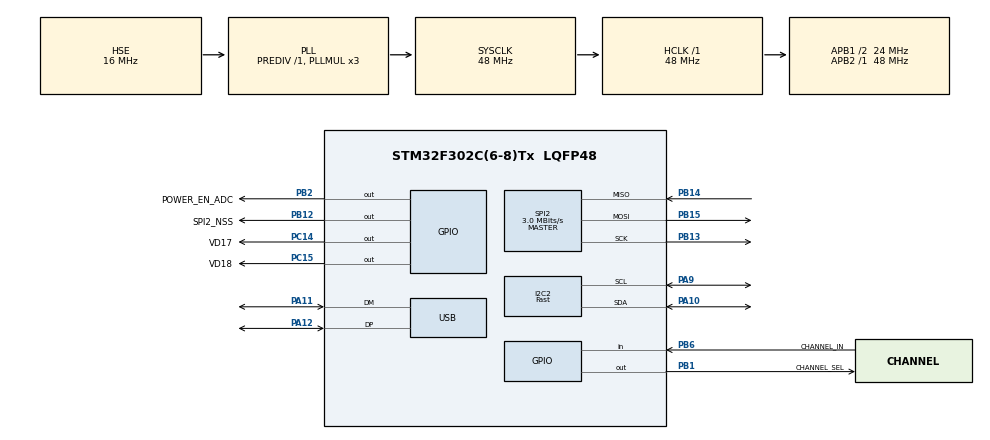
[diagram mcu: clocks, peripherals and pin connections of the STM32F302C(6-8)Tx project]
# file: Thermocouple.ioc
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I2C2.I2C_Speed_Mode=I2C_Fast
I2C2.Timing=0x0000020B
Mcu.Family=STM32F3
Mcu.Name=STM32F302C(6-8)Tx
Mcu.Package=LQFP48
NVIC.PriorityGroup=NVIC_PRIORITYGROUP_4
NVIC.USB_LP_CAN_RX0_IRQn=true\:0\:0\:false\:false\:true\:false\:true
PA10.Mode=I2C
PA10.Signal=I2C2_SDA
PA11.Mode=Device
PA11.Signal=USB_DM
PA12.Mode=Device
PA12.Signal=USB_DP
PA13.Mode=Serial_Wire
PA13.Signal=SYS_JTMS-SWDIO
PA14.Mode=Serial_Wire
PA14.Signal=SYS_JTCK-SWCLK
PA9.Mode=I2C
PA9.Signal=I2C2_SCL
PB1.GPIO_Label=CHANNEL_SEL
PB1.Signal=GPIO_Output
PB12.GPIO_Label=SPI2_NSS
PB12.GPIO_Speed=GPIO_SPEED_FREQ_HIGH
PB12.PinState=GPIO_PIN_SET
PB12.Signal=GPIO_Output
PB13.Mode=Full_Duplex_Master
PB13.Signal=SPI2_SCK
PB14.Mode=Full_Duplex_Master
PB14.Signal=SPI2_MISO
PB15.Mode=Full_Duplex_Master
PB15.Signal=SPI2_MOSI
PB2.GPIO_Label=POWER_EN_ADC
PB2.Signal=GPIO_Output
PB6.GPIO_Label=CHANNEL_IN
PB6.GPIO_PuPd=GPIO_PULLUP
PB6.Signal=GPIO_Input
PC14\ -\ OSC32_IN.GPIO_Label=VD17
PC14\ -\ OSC32_IN.Signal=GPIO_Output
PC15\ -\ OSC32_OUT.GPIO_Label=VD18
PC15\ -\ OSC32_OUT.Signal=GPIO_Output
PF0-OSC_IN.Mode=HSE-External-Oscillator
PF0-OSC_IN.Signal=RCC_OSC_IN
PF1-OSC_OUT.Mode=HSE-External-Oscillator
PF1-OSC_OUT.Signal=RCC_OSC_OUT
ProjectManager.HeapSize=0x200
ProjectManager.StackSize=0x400
ProjectManager.TargetToolchain=STM32CubeIDE
RCC.AHBFreq_Value=48000000
RCC.APB1CLKDivider=RCC_HCLK_DIV2
RCC.APB1Freq_Value=24000000
RCC.APB1TimFreq_Value=48000000
RCC.APB2Freq_Value=48000000
RCC.APB2TimFreq_Value=48000000
RCC.CortexFreq_Value=48000000
RCC.HCLKFreq_Value=48000000
RCC.HSE_VALUE=16000000
RCC.HSI_VALUE=8000000
RCC.LSE_VALUE=32768
RCC.PLLMUL=RCC_PLL_MUL3
RCC.SYSCLKFreq_VALUE=48000000
RCC.SYSCLKSourceVirtual=RCC_SYSCLKSOURCE_PLLCLK
RCC.USBFreq_Value=48000000
SPI2.BaudRatePrescaler=SPI_BAUDRATEPRESCALER_8
SPI2.CLKPhase=SPI_PHASE_2EDGE
SPI2.CalculateBaudRate=3.0 MBits/s
SPI2.DataSize=SPI_DATASIZE_8BIT
SPI2.Direction=SPI_DIRECTION_2LINES
SPI2.Mode=SPI_MODE_MASTER
SPI2.VirtualType=VM_MASTER
USB_DEVICE.CLASS_NAME_FS=CDC
USB_DEVICE.VirtualMode=Cdc
USB_DEVICE.VirtualModeFS=Cdc_FS
VP_USB_DEVICE_VS_USB_DEVICE_CDC_FS.Mode=CDC_FS
board=custom

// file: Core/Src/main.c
/* USER CODE BEGIN Header */
/**
  ******************************************************************************
  * @file           : main.c
  * @brief          : Main program body
  ******************************************************************************
  * @attention
  *
  * <h2><center>&copy; Copyright (c) 2021 STMicroelectronics.
  * All rights reserved.</center></h2>
  *
  * This software component is licensed by ST under BSD 3-Clause license,
  * the "License"; You may not use this file except in compliance with the
  * License. You may obtain a copy of the License at:
  *                        opensource.org/licenses/BSD-3-Clause
  *
  ******************************************************************************
  */
/* USER CODE END Header */
#include "main.h"
#include "usb_device.h"

/* USER CODE BEGIN Includes */
#include "thermocouple.h"
/* USER CODE END Includes */

I2C_HandleTypeDef hi2c2;

SPI_HandleTypeDef hspi2;

void SystemClock_Config(void);
static void MX_GPIO_Init(void);
static void MX_SPI2_Init(void);
static void MX_I2C2_Init(void);

int main(void)
{

  /* MCU Configuration--------------------------------------------------------*/

  /* Reset of all peripherals, Initializes the Flash interface and the Systick. */
  HAL_Init();

  /* Configure the system clock */
  SystemClock_Config();

  /* Initialize all configured peripherals */
  MX_GPIO_Init();
  MX_SPI2_Init();
  MX_USB_DEVICE_Init();
  MX_I2C2_Init();
  /* USER CODE BEGIN 2 */
  POWER_EN_ADC_GPIO_Port->BSRR = (uint32_t)POWER_EN_ADC_Pin;  //+3,3A_ISO1(DA3), +3,3V_ISO1(DA4) -- ON
  //CHANNEL_SEL_GPIO_Port->BSRR   = (uint32_t)CHANNEL_SEL_Pin;   //Analog Switches COM1 or COM2
  CHANNEL_SEL_GPIO_Port->BRR   = (uint32_t)CHANNEL_SEL_Pin;   //Analog Switches COM1 or COM2

  VD17_GPIO_Port->BSRR = (uint32_t)VD17_Pin;
  VD18_GPIO_Port->BSRR = (uint32_t)VD18_Pin;

  init_TMP112();
  MAX31856_config();
  /* USER CODE END 2 */

  /* Infinite loop */
  /* USER CODE BEGIN WHILE */
  while (1)
  {
    if(CHANNEL_IN_GPIO_Port->IDR & CHANNEL_IN_Pin)
      CHANNEL_SEL_GPIO_Port->BRR  = (uint32_t)CHANNEL_SEL_Pin;   //Analog Switches COM1 or COM2, MAX31856
    else
      CHANNEL_SEL_GPIO_Port->BSRR = (uint32_t)CHANNEL_SEL_Pin;   //Analog Switches COM1 or COM2
    MAX31856_read();
    read_TMP112();

    send_data();  //USB COM-port
    /* USER CODE END WHILE */

  }
}

void SystemClock_Config(void)
{
  RCC_OscInitTypeDef RCC_OscInitStruct = {0};
  RCC_ClkInitTypeDef RCC_ClkInitStruct = {0};
  RCC_PeriphCLKInitTypeDef PeriphClkInit = {0};

  /** Initializes the RCC Oscillators according to the specified parameters
  * in the RCC_OscInitTypeDef structure.
  */
  RCC_OscInitStruct.OscillatorType = RCC_OSCILLATORTYPE_HSI|RCC_OSCILLATORTYPE_HSE;
  RCC_OscInitStruct.HSEState = RCC_HSE_ON;
  RCC_OscInitStruct.HSEPredivValue = RCC_HSE_PREDIV_DIV1;
  RCC_OscInitStruct.HSIState = RCC_HSI_ON;
  RCC_OscInitStruct.HSICalibrationValue = RCC_HSICALIBRATION_DEFAULT;
  RCC_OscInitStruct.PLL.PLLState = RCC_PLL_ON;
  RCC_OscInitStruct.PLL.PLLSource = RCC_PLLSOURCE_HSE;
  RCC_OscInitStruct.PLL.PLLMUL = RCC_PLL_MUL3;
  if (HAL_RCC_OscConfig(&RCC_OscInitStruct) != HAL_OK)
  {
    Error_Handler();
  }
  /** Initializes the CPU, AHB and APB buses clocks
  */
  RCC_ClkInitStruct.ClockType = RCC_CLOCKTYPE_HCLK|RCC_CLOCKTYPE_SYSCLK
                              |RCC_CLOCKTYPE_PCLK1|RCC_CLOCKTYPE_PCLK2;
  RCC_ClkInitStruct.SYSCLKSource = RCC_SYSCLKSOURCE_PLLCLK;
  RCC_ClkInitStruct.AHBCLKDivider = RCC_SYSCLK_DIV1;
  RCC_ClkInitStruct.APB1CLKDivider = RCC_HCLK_DIV2;
  RCC_ClkInitStruct.APB2CLKDivider = RCC_HCLK_DIV1;

  if (HAL_RCC_ClockConfig(&RCC_ClkInitStruct, FLASH_LATENCY_1) != HAL_OK)
  {
    Error_Handler();
  }
  PeriphClkInit.PeriphClockSelection = RCC_PERIPHCLK_USB|RCC_PERIPHCLK_I2C2;
  PeriphClkInit.I2c2ClockSelection = RCC_I2C2CLKSOURCE_HSI;
  PeriphClkInit.USBClockSelection = RCC_USBCLKSOURCE_PLL;
  if (HAL_RCCEx_PeriphCLKConfig(&PeriphClkInit) != HAL_OK)
  {
    Error_Handler();
  }
}

static void MX_I2C2_Init(void)
{

  hi2c2.Instance = I2C2;
  hi2c2.Init.Timing = 0x0000020B;
  hi2c2.Init.OwnAddress1 = 0;
  hi2c2.Init.AddressingMode = I2C_ADDRESSINGMODE_7BIT;
  hi2c2.Init.DualAddressMode = I2C_DUALADDRESS_DISABLE;
  hi2c2.Init.OwnAddress2 = 0;
  hi2c2.Init.OwnAddress2Masks = I2C_OA2_NOMASK;
  hi2c2.Init.GeneralCallMode = I2C_GENERALCALL_DISABLE;
  hi2c2.Init.NoStretchMode = I2C_NOSTRETCH_DISABLE;
  if (HAL_I2C_Init(&hi2c2) != HAL_OK)
  {
    Error_Handler();
  }
  /** Configure Analogue filter
  */
  if (HAL_I2CEx_ConfigAnalogFilter(&hi2c2, I2C_ANALOGFILTER_ENABLE) != HAL_OK)
  {
    Error_Handler();
  }
  /** Configure Digital filter
  */
  if (HAL_I2CEx_ConfigDigitalFilter(&hi2c2, 0) != HAL_OK)
  {
    Error_Handler();
  }

}

static void MX_SPI2_Init(void)
{

  /* SPI2 parameter configuration*/
  hspi2.Instance = SPI2;
  hspi2.Init.Mode = SPI_MODE_MASTER;
  hspi2.Init.Direction = SPI_DIRECTION_2LINES;
  hspi2.Init.DataSize = SPI_DATASIZE_8BIT;
  hspi2.Init.CLKPolarity = SPI_POLARITY_LOW;
  hspi2.Init.CLKPhase = SPI_PHASE_2EDGE;
  hspi2.Init.NSS = SPI_NSS_SOFT;
  hspi2.Init.BaudRatePrescaler = SPI_BAUDRATEPRESCALER_8;
  hspi2.Init.FirstBit = SPI_FIRSTBIT_MSB;
  hspi2.Init.TIMode = SPI_TIMODE_DISABLE;
  hspi2.Init.CRCCalculation = SPI_CRCCALCULATION_DISABLE;
  hspi2.Init.CRCPolynomial = 7;
  hspi2.Init.CRCLength = SPI_CRC_LENGTH_DATASIZE;
  hspi2.Init.NSSPMode = SPI_NSS_PULSE_DISABLE;
  if (HAL_SPI_Init(&hspi2) != HAL_OK)
  {
    Error_Handler();
  }

}

static void MX_GPIO_Init(void)
{
  GPIO_InitTypeDef GPIO_InitStruct = {0};

  /* GPIO Ports Clock Enable */
  __HAL_RCC_GPIOC_CLK_ENABLE();
  __HAL_RCC_GPIOF_CLK_ENABLE();
  __HAL_RCC_GPIOB_CLK_ENABLE();
  __HAL_RCC_GPIOA_CLK_ENABLE();

  /*Configure GPIO pin Output Level */
  HAL_GPIO_WritePin(GPIOC, VD17_Pin|VD18_Pin, GPIO_PIN_RESET);

  /*Configure GPIO pin Output Level */
  HAL_GPIO_WritePin(GPIOB, CHANNEL_SEL_Pin|POWER_EN_ADC_Pin, GPIO_PIN_RESET);

  /*Configure GPIO pin Output Level */
  HAL_GPIO_WritePin(SPI2_NSS_GPIO_Port, SPI2_NSS_Pin, GPIO_PIN_SET);

  /*Configure GPIO pins : VD17_Pin VD18_Pin */
  GPIO_InitStruct.Pin = VD17_Pin|VD18_Pin;
  GPIO_InitStruct.Mode = GPIO_MODE_OUTPUT_PP;
  GPIO_InitStruct.Pull = GPIO_NOPULL;
  GPIO_InitStruct.Speed = GPIO_SPEED_FREQ_LOW;
  HAL_GPIO_Init(GPIOC, &GPIO_InitStruct);

  /*Configure GPIO pins : CHANNEL_SEL_Pin POWER_EN_ADC_Pin */
  GPIO_InitStruct.Pin = CHANNEL_SEL_Pin|POWER_EN_ADC_Pin;
  GPIO_InitStruct.Mode = GPIO_MODE_OUTPUT_PP;
  GPIO_InitStruct.Pull = GPIO_NOPULL;
  GPIO_InitStruct.Speed = GPIO_SPEED_FREQ_LOW;
  HAL_GPIO_Init(GPIOB, &GPIO_InitStruct);

  /*Configure GPIO pin : SPI2_NSS_Pin */
  GPIO_InitStruct.Pin = SPI2_NSS_Pin;
  GPIO_InitStruct.Mode = GPIO_MODE_OUTPUT_PP;
  GPIO_InitStruct.Pull = GPIO_NOPULL;
  GPIO_InitStruct.Speed = GPIO_SPEED_FREQ_HIGH;
  HAL_GPIO_Init(SPI2_NSS_GPIO_Port, &GPIO_InitStruct);

  /*Configure GPIO pin : CHANNEL_IN_Pin */
  GPIO_InitStruct.Pin = CHANNEL_IN_Pin;
  GPIO_InitStruct.Mode = GPIO_MODE_INPUT;
  GPIO_InitStruct.Pull = GPIO_PULLUP;
  HAL_GPIO_Init(CHANNEL_IN_GPIO_Port, &GPIO_InitStruct);

}

void Error_Handler(void)
{
  __disable_irq();
  while (1)
  {
  }
}

/************************ (C) COPYRIGHT STMicroelectronics *****END OF FILE****/
